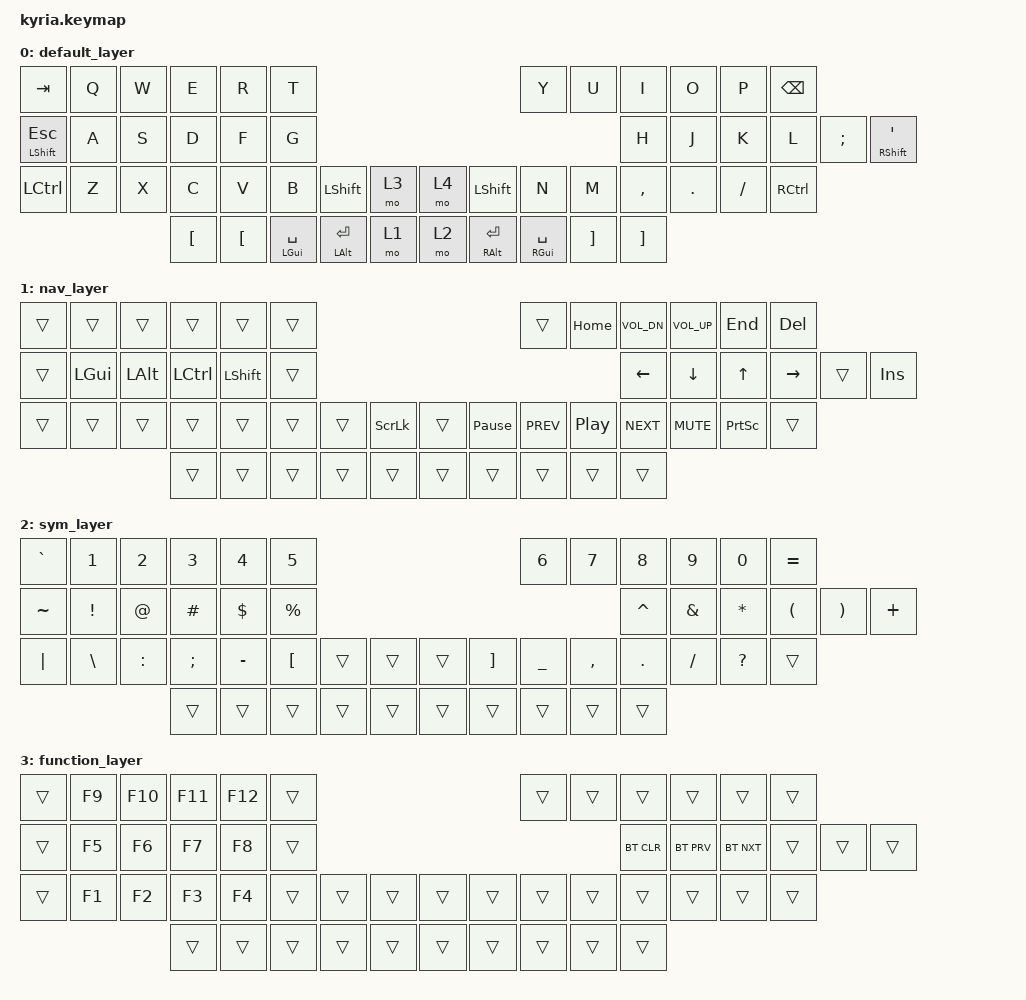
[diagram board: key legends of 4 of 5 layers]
/*
 * Copyright (c) 2020 The ZMK Contributors
 *
 * SPDX-License-Identifier: MIT
 */
#include <behaviors.dtsi>
#include <dt-bindings/zmk/bt.h>
#include <dt-bindings/zmk/keys.h>

/ {
    keymap {
        compatible = "zmk,keymap";


        default_layer {
            bindings = <
                &kp TAB         &kp Q &kp W &kp E &kp R &kp T                                                   &kp Y &kp U  &kp I     &kp O   &kp P    &kp BSPC
                &mt LSHFT ESC   &kp A &kp S &kp D &kp F &kp G                                                   &kp H &kp J  &kp K     &kp L   &kp SEMI &mt RSHIFT SQT
                &kp LCTRL       &kp Z &kp X &kp C &kp V &kp B          &kp LSHFT &mo 3          &mo 4    &kp LSHFT  &kp N &kp M  &kp COMMA &kp DOT &kp FSLH &kp RCTRL
                          &kp LBKT &kp LBKT &mt LGUI SPACE &mt LALT RET &mo 1        &mo 2  &mt RALT RET  &mt RGUI SPACE &kp RBKT &kp RBKT
            >;
        };

        nav_layer {
            bindings = <
                &trans     &trans &trans &trans &trans &trans                                           &trans &kp HOME &kp C_VOL_DN &kp C_VOL_UP &kp END   &kp DEL
                &trans     &kp LGUI &kp LALT &kp LCTRL &kp LSHFT &trans                                 &kp LEFT &kp DOWN &kp UP &kp RIGHT &trans &kp INS
                &trans     &trans &trans &trans &trans &trans &trans &kp SLCK &trans &kp PAUSE_BREAK     &kp C_PREV &kp C_PP &kp C_NEXT &kp C_MUTE &kp PSCRN &trans
                                        &trans &trans &trans &trans &trans &trans &trans &trans &trans &trans
            >;
        };

        sym_layer {
            bindings = <
                &kp GRAVE  &kp N1 &kp N2 &kp N3 &kp N4 &kp N5                                           &kp N6 &kp N7 &kp N8 &kp N9 &kp N0 &kp EQUAL
                &kp TILDE  &kp EXCL &kp AT &kp HASH &kp DLLR &kp PRCNT                                  &kp CARET &kp AMPS &kp STAR &kp LPAR &kp RPAR &kp PLUS
                &kp PIPE   &kp BSLH &kp COLON &kp SEMI &kp MINUS &kp LBKT &trans &trans &trans &kp RBKT &kp UNDER &kp COMMA &kp DOT &kp FSLH &kp QMARK &trans
                                        &trans &trans &trans &trans &trans &trans &trans &trans &trans &trans
            >;
        };

        function_layer {
            bindings = <
                &trans     &kp F9 &kp F10 &kp F11 &kp F12 &trans                                        &trans &trans &trans &trans &trans &trans
                &trans     &kp F5 &kp F6 &kp F7 &kp F8 &trans                                           &bt BT_CLR &bt BT_PRV &bt BT_NXT &trans &trans &trans
                &trans     &kp F1 &kp F2 &kp F3 &kp F4 &trans &trans &trans &trans &trans               &trans &trans &trans &trans &trans &trans
                                            &trans &trans &trans &trans &trans &trans &trans &trans &trans &trans
            >;
        };

        adjust_layer {
            bindings = <
                &to 0      &trans &trans &trans &trans &trans &trans                                           &trans &trans &trans &trans &trans &trans
                &to 1      &trans &trans &trans &trans &trans &trans                                           &trans &trans &trans &trans &trans &trans
                &to 2      &trans &trans &trans &trans &trans &trans                                           &trans &trans &trans &trans &trans &trans
                                        &trans &trans &trans &trans &trans &trans &trans &trans &trans &trans
            >;
        };
    };
};
